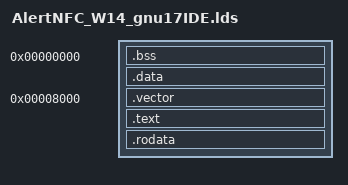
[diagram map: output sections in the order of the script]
/* Linker Script file generated by Gnu17 Plug-in for Eclipse */
OUTPUT_FORMAT("elf32-c17", "elf32-c17", "elf32-c17")
OUTPUT_ARCH(c17)
SEARCH_DIR(.);

SECTIONS
{

	/* stack pointer symbols */
	__START_stack = 0x000FC0;

	/* location counter */
	. = 0x0;

	/* section information */
	.bss 0x000000 : 
	  {
	   __START_bss = . ;
	   src/boot.o(.bss)
	   src/clg.o(.bss)
	   src/eeprom.o(.bss)
	   src/i2c_mst.o(.bss)
	   src/init.o(.bss)
	   src/key.o(.bss)
	   src/lcd8b.o(.bss)
	   src/main.o(.bss)
	   src/port.o(.bss)
	   src/pwg2.o(.bss)
	   src/rfc.o(.bss)
	   src/rtca.o(.bss)
	   src/svd.o(.bss)
	   src/t16_ch0.o(.bss)
	   src/uart.o(.bss)
	   C:/EPSON/GNU17/lib/24bit/libstdio.a(.bss)
	   C:/EPSON/GNU17/lib/24bit/libc.a(.bss)
	   C:/EPSON/GNU17/lib/24bit/libgcc.a(.bss)
	   C:/EPSON/GNU17/lib/24bit/libc.a(.bss)
	  }
	  __END_bss = . ;

	.data __END_bss : AT( __END_rodata )
	  {
	   __START_data = . ;
	   src/boot.o(.data)
	   src/clg.o(.data)
	   src/eeprom.o(.data)
	   src/i2c_mst.o(.data)
	   src/init.o(.data)
	   src/key.o(.data)
	   src/lcd8b.o(.data)
	   src/main.o(.data)
	   src/port.o(.data)
	   src/pwg2.o(.data)
	   src/rfc.o(.data)
	   src/rtca.o(.data)
	   src/svd.o(.data)
	   src/t16_ch0.o(.data)
	   src/uart.o(.data)
	   C:/EPSON/GNU17/lib/24bit/libstdio.a(.data)
	   C:/EPSON/GNU17/lib/24bit/libc.a(.data)
	   C:/EPSON/GNU17/lib/24bit/libgcc.a(.data)
	   C:/EPSON/GNU17/lib/24bit/libc.a(.data)
	  }
	  __END_data = . ;

	.vector 0x008000 : 
	  {
	   __START_vector = . ;
	   src/boot.o(.rodata)
	  }
	  __END_vector = . ;

	.text __END_vector : 
	  {
	   __START_text = . ;
	   src/boot.o(.text)
	   src/clg.o(.text)
	   src/eeprom.o(.text)
	   src/i2c_mst.o(.text)
	   src/init.o(.text)
	   src/key.o(.text)
	   src/lcd8b.o(.text)
	   src/main.o(.text)
	   src/port.o(.text)
	   src/pwg2.o(.text)
	   src/rfc.o(.text)
	   src/rtca.o(.text)
	   src/svd.o(.text)
	   src/t16_ch0.o(.text)
	   src/uart.o(.text)
	   C:/EPSON/GNU17/lib/24bit/libstdio.a(.text)
	   C:/EPSON/GNU17/lib/24bit/libc.a(.text)
	   C:/EPSON/GNU17/lib/24bit/libgcc.a(.text)
	   C:/EPSON/GNU17/lib/24bit/libc.a(.text)
	  }
	  __END_text = . ;

	.rodata __END_text : 
	  {
	   __START_rodata = . ;
	   src/clg.o(.rodata)
	   src/eeprom.o(.rodata)
	   src/i2c_mst.o(.rodata)
	   src/init.o(.rodata)
	   src/key.o(.rodata)
	   src/lcd8b.o(.rodata)
	   src/main.o(.rodata)
	   src/port.o(.rodata)
	   src/pwg2.o(.rodata)
	   src/rfc.o(.rodata)
	   src/rtca.o(.rodata)
	   src/svd.o(.rodata)
	   src/t16_ch0.o(.rodata)
	   src/uart.o(.rodata)
	   C:/EPSON/GNU17/lib/24bit/libstdio.a(.rodata)
	   C:/EPSON/GNU17/lib/24bit/libc.a(.rodata)
	   C:/EPSON/GNU17/lib/24bit/libgcc.a(.rodata)
	   C:/EPSON/GNU17/lib/24bit/libc.a(.rodata)
	  }
	  __END_rodata = . ;

	  __START_data_lma = __END_rodata ;
	  __END_data_lma = __END_rodata + ( __END_data - __START_data );

}
